# R7FA4W1AD register map
Vendor: Renesas; Series: RA4; File version: 1.0
CPU: CM4 r0p1, little endian, MPU, FPU, VTOR, 4 interrupt priority bits
Registers are 8-bit, read-write, reset 0x0 unless marked. A register's access mark holds for its fields unless they carry their own. Offsets are from the block's base; [hi:lo] are bit positions; {n}, {i} and the like mark numbered series.

## POEG — Port Output Enable Module for GPT
Base 0x40042000
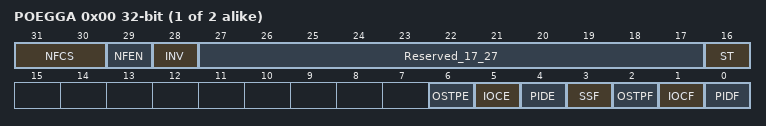
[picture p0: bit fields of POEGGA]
0x00 POEGG{x} (x=A,B; step 0x100) 32-bit — POEG Group {x} Setting Register
  [31:30] NFCS — Noise Filter Clock Select
  [29] NFEN — Noise Filter Enable
  [28] INV — GTETRG Input Reverse
  [27:17] Reserved_17_27 — These bits are read as 00000000000. The write value should be 00000000000.
  [16] ST ro — GTETRG Input Status Flag
  [6] OSTPE — Oscillation Stop Detection EnableNote: Can be modified only once after a reset.
  [5] IOCE — Output,disable Request Enable from GPTNote: Can be modified only once after a reset.
  [4] PIDE — Port Input Detection EnableNote: Can be modified only once after a reset.
  [3] SSF — Software Stop Flag
  [2] OSTPF write-0-clears read-modifies — Oscillation Stop Detection Flag
  [1] IOCF write-0-clears read-modifies — Output,disable Request Detection Flag from GPT
  [0] PIDF write-0-clears read-modifies — Port Input Detection Flag

## GPT_OPS — Output Phase Switching Controller
Base 0x40078FF0
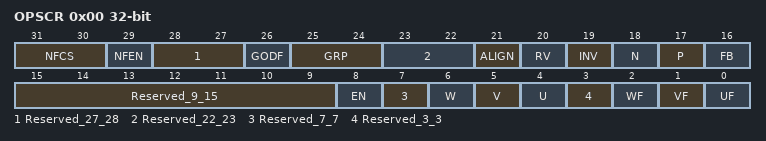
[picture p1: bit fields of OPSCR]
0x00 OPSCR 32-bit — Output Phase Switching Control Register
  [31:30] NFCS — External Input Noise Filter Clock selectionNoise filter sampling clock setting of the external input.
  [29] NFEN — External Input Noise Filter Enable
  [28:27] Reserved_27_28 — These bits are read as 00. The write value should be 00.
  [26] GODF — Group output disable function
  [25:24] GRP — Output disabled source selection
  [23:22] Reserved_22_23 — These bits are read as 00. The write value should be 00.
  [21] ALIGN — Input phase alignment
  [20] RV — Output phase rotation direction reversal
  [19] INV — Invert,Phase Output Control
  [18] N — Negative,Phase Output (N) Control
  [17] P — Positive,Phase Output (P) Control
  [16] FB — External Feedback Signal EnableThis bit selects the input phase from the software settings and external input.
  [15:9] Reserved_9_15 — These bits are read as 0000000. The write value should be 0000000.
  [8] EN — Enable,Phase Output Control
  [7] Reserved_7_7 — This bit is read as 0. The write value should be 0.
  [6] W ro — Input W,Phase MonitorThis bit monitors the state of the input phase.OPSCR.FB=0:External input monitoring by PCLKOPSCR.FB=1:Software settings (UF/VF/WF)
  [5] V ro — Input V,Phase MonitorThis bit monitors the state of the input phase.OPSCR.FB=0:External input monitoring by PCLKOPSCR.FB=1:Software settings (UF/VF/WF)
  [4] U ro — Input U,Phase MonitorThis bit monitors the state of the input phase.OPSCR.FB=0:External input monitoring by PCLKOPSCR.FB=1:Software settings (UF/VF/WF)
  [3] Reserved_3_3 — This bit is read as 0. The write value should be 0.
  [2] WF — Input Phase Soft Setting UFThis bit sets the input phase by the software settings.This bit setting is valid when the OPSCR.FB bit = 1.
  [1] VF — Input Phase Soft Setting VFThis bit sets the input phase by the software settings.This bit setting is valid when the OPSCR.FB bit = 1.
  [0] UF — Input Phase Soft Setting WFThis bit sets the input phase by the software settings.This bit setting is valid when the OPSCR.FB bit = 1.

## AGT0 — Asynchronous General purpose Timer 0
Base 0x40084000
Same registers: AGT1 0x40084100
0x00 AGT 16-bit reset 0xFFFF — AGT Counter Register
  [15:0] AGT — 16bit counter and reload registerNOTE : When 1 is written to the TSTOP bit in the AGTCRn register, the 16-bit counter is forcibly stopped and set to FFFFH.
0x02 AGTCMA 16-bit reset 0xFFFF — AGT Compare Match A Register
  [15:0] AGTCMA — AGT Compare Match A data is stored.NOTE : When 1 is written to the TSTOP bit in the AGTCRn register, set to FFFFH
0x04 AGTCMB 16-bit reset 0xFFFF — AGT Compare Match B Register
  [15:0] AGTCMB — AGT Compare Match B data is stored.NOTE : When 1 is written to the TSTOP bit in the AGTCR register, set to FFFFH
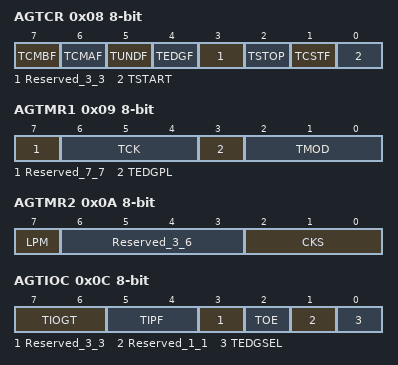
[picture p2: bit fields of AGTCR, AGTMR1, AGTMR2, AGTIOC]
0x08 AGTCR — AGT Control Register
  [7] TCMBF write-0-clears read-modifies — Compare match B flag
  [6] TCMAF write-0-clears read-modifies — Compare match A flag
  [5] TUNDF write-0-clears read-modifies — Underflow flag
  [4] TEDGF write-0-clears read-modifies — Active edge judgment flag
  [3] Reserved_3_3 — This bit is read as 0. The write value should be 0.
  [2] TSTOP wo — AGT count forced stop
  [1] TCSTF ro — AGT count status flag
  [0] TSTART — AGT count start
0x09 AGTMR1 — AGT Mode Register 1
  [7] Reserved_7_7 — This bit is read as 0. The write value should be 0.
  [6:4] TCK — Count source
  [3] TEDGPL — Edge polarity
  [2:0] TMOD — Operating mode
0x0A AGTMR2 — AGT Mode Register 2
  [7] LPM — Low Power Mode
  [6:3] Reserved_3_6 — These bits are read as 0000. The write value should be 0000.
  [2:0] CKS — AGTLCLK/AGTSCLK count source clock frequency division ratio
0x0C AGTIOC — AGT I/O Control Register
  [7:6] TIOGT — Count control
  [5:4] TIPF — Input filter
  [3] Reserved_3_3 — This bit is read as 0. The write value should be 0.
  [2] TOE — AGTOn output enable
  [1] Reserved_1_1 — This bit is read as 0. The write value should be 0.
  [0] TEDGSEL — I/O polarity switchFunction varies depending on the operating mode.
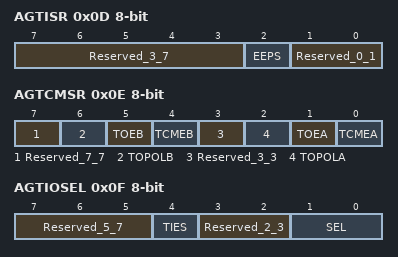
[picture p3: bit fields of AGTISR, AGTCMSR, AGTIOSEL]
0x0D AGTISR — AGT Event Pin Select Register
  [7:3] Reserved_3_7 — These bits are read as 00000. The write value should be 00000.
  [2] EEPS — AGTEE polarty selection
  [1:0] Reserved_0_1 — These bits are read as 00. The write value should be 00.
0x0E AGTCMSR — AGT Compare Match Function Select Register
  [7] Reserved_7_7 — This bit is read as 0. The write value should be 0.
  [6] TOPOLB — AGTOB polarity select
  [5] TOEB — AGTOB output enable
  [4] TCMEB — Compare match B register enable
  [3] Reserved_3_3 — This bit is read as 0. The write value should be 0.
  [2] TOPOLA — AGTOA polarity select
  [1] TOEA — AGTOA output enable
  [0] TCMEA — Compare match A register enable
0x0F AGTIOSEL — AGT Pin Select Register
  [7:5] Reserved_5_7 — These bits are read as 000. The write value should be 000.
  [4] TIES — AGTIO input enable
  [3:2] Reserved_2_3 — These bits are read as 00. The write value should be 00.
  [1:0] SEL — AGTIO pin select
